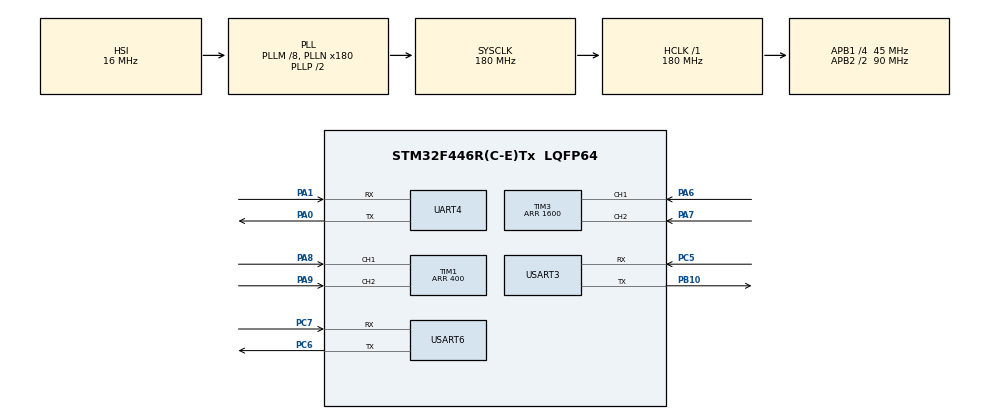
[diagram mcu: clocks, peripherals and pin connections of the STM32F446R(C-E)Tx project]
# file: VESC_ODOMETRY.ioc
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Dma.Request0=USART6_RX
Dma.Request1=UART4_RX
Dma.UART4_RX.1.Direction=DMA_PERIPH_TO_MEMORY
Dma.UART4_RX.1.FIFOMode=DMA_FIFOMODE_DISABLE
Dma.UART4_RX.1.Instance=DMA1_Stream2
Dma.UART4_RX.1.MemDataAlignment=DMA_MDATAALIGN_BYTE
Dma.UART4_RX.1.MemInc=DMA_MINC_ENABLE
Dma.UART4_RX.1.Mode=DMA_CIRCULAR
Dma.UART4_RX.1.PeriphDataAlignment=DMA_PDATAALIGN_BYTE
Dma.UART4_RX.1.PeriphInc=DMA_PINC_DISABLE
Dma.UART4_RX.1.Priority=DMA_PRIORITY_LOW
Dma.USART6_RX.0.Direction=DMA_PERIPH_TO_MEMORY
Dma.USART6_RX.0.FIFOMode=DMA_FIFOMODE_DISABLE
Dma.USART6_RX.0.Instance=DMA2_Stream1
Dma.USART6_RX.0.MemDataAlignment=DMA_MDATAALIGN_BYTE
Dma.USART6_RX.0.MemInc=DMA_MINC_ENABLE
Dma.USART6_RX.0.Mode=DMA_CIRCULAR
Dma.USART6_RX.0.PeriphDataAlignment=DMA_PDATAALIGN_BYTE
Dma.USART6_RX.0.PeriphInc=DMA_PINC_DISABLE
Dma.USART6_RX.0.Priority=DMA_PRIORITY_LOW
FREERTOS.Tasks01=Motor_run,24,128,motor_run_function,Default,NULL,Dynamic,NULL,NULL
Mcu.Family=STM32F4
Mcu.Name=STM32F446R(C-E)Tx
Mcu.Package=LQFP64
NVIC.DMA1_Stream2_IRQn=true\:5\:0\:false\:false\:true\:true\:false\:true\:true
NVIC.DMA2_Stream1_IRQn=true\:5\:0\:false\:false\:true\:true\:false\:true\:true
NVIC.PriorityGroup=NVIC_PRIORITYGROUP_4
PA0-WKUP.Mode=Asynchronous
PA0-WKUP.Signal=UART4_TX
PA1.Mode=Asynchronous
PA1.Signal=UART4_RX
PA13.Mode=Serial_Wire
PA13.Signal=SYS_JTMS-SWDIO
PA14.Mode=Serial_Wire
PA14.Signal=SYS_JTCK-SWCLK
PA6.Signal=S_TIM3_CH1
PA7.Signal=S_TIM3_CH2
PA8.Signal=S_TIM1_CH1
PA9.Signal=S_TIM1_CH2
PB10.Mode=Asynchronous
PB10.Signal=USART3_TX
PC5.Mode=Asynchronous
PC5.Signal=USART3_RX
PC6.Mode=Asynchronous
PC6.Signal=USART6_TX
PC7.Mode=Asynchronous
PC7.Signal=USART6_RX
PH0-OSC_IN.Mode=HSE-External-Oscillator
PH0-OSC_IN.Signal=RCC_OSC_IN
PH1-OSC_OUT.Mode=HSE-External-Oscillator
PH1-OSC_OUT.Signal=RCC_OSC_OUT
ProjectManager.HeapSize=0x200
ProjectManager.StackSize=0x400
ProjectManager.TargetToolchain=STM32CubeIDE
RCC.AHBFreq_Value=180000000
RCC.APB1CLKDivider=RCC_HCLK_DIV4
RCC.APB1Freq_Value=45000000
RCC.APB1TimFreq_Value=90000000
RCC.APB2CLKDivider=RCC_HCLK_DIV2
RCC.APB2Freq_Value=90000000
RCC.APB2TimFreq_Value=180000000
RCC.CortexFreq_Value=180000000
RCC.HCLKFreq_Value=180000000
RCC.PLLM=8
RCC.PLLN=180
RCC.SYSCLKFreq_VALUE=180000000
RCC.SYSCLKSource=RCC_SYSCLKSOURCE_PLLCLK
RCC.USBFreq_Value=180000000
RCC.VCOOutputFreq_Value=360000000
SH.S_TIM1_CH1.0=TIM1_CH1,Encoder_Interface
SH.S_TIM1_CH2.0=TIM1_CH2,Encoder_Interface
SH.S_TIM3_CH1.0=TIM3_CH1,Encoder_Interface
SH.S_TIM3_CH2.0=TIM3_CH2,Encoder_Interface
TIM1.AutoReloadPreload=TIM_AUTORELOAD_PRELOAD_ENABLE
TIM1.EncoderMode=TIM_ENCODERMODE_TI12
TIM1.Period=400
TIM2.Period=90000
TIM3.AutoReloadPreload=TIM_AUTORELOAD_PRELOAD_ENABLE
TIM3.EncoderMode=TIM_ENCODERMODE_TI12
TIM3.Period=1600
UART4.VirtualMode=Asynchronous
USART3.VirtualMode=VM_ASYNC
USART6.VirtualMode=VM_ASYNC
VP_FREERTOS_VS_CMSIS_V2.Mode=CMSIS_V2
VP_TIM2_VS_ClockSourceINT.Mode=Internal
board=custom

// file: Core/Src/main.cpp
/* USER CODE BEGIN Header */
/**
  ******************************************************************************
  * @file           : main.c
  * @brief          : Main program body
  ******************************************************************************
  * @attention
  *
  * Copyright (c) 2025 STMicroelectronics.
  * All rights reserved.
  *
  * This software is licensed under terms that can be found in the LICENSE file
  * in the root directory of this software component.
  * If no LICENSE file comes with this software, it is provided AS-IS.
  *
  ******************************************************************************
  */
/* USER CODE END Header */
#include "main.h"
#include "cmsis_os.h"

/* USER CODE BEGIN Includes */
#include "VescUart.h"

/* USER CODE END Includes */

TIM_HandleTypeDef htim1;
TIM_HandleTypeDef htim2;
TIM_HandleTypeDef htim3;

UART_HandleTypeDef huart4;
UART_HandleTypeDef huart3;
UART_HandleTypeDef huart6;
DMA_HandleTypeDef hdma_uart4_rx;
DMA_HandleTypeDef hdma_usart6_rx;

/* Definitions for Motor_run */
osThreadId_t Motor_runHandle;
const osThreadAttr_t Motor_run_attributes = {
  .name = "Motor_run",
  .stack_size = 128 * 4,
  .priority = (osPriority_t) osPriorityNormal,
};

void SystemClock_Config(void);
static void MX_GPIO_Init(void);
static void MX_DMA_Init(void);
static void MX_TIM1_Init(void);
static void MX_TIM3_Init(void);
static void MX_UART4_Init(void);
static void MX_USART3_UART_Init(void);
static void MX_USART6_UART_Init(void);
static void MX_TIM2_Init(void);
void motor_run_function(void *argument);

/* USER CODE BEGIN 0 */
VescUart vesc;
  // Motor 1
/* USER CODE END 0 */

int main(void)
{

  /* MCU Configuration--------------------------------------------------------*/

  /* Reset of all peripherals, Initializes the Flash interface and the Systick. */
  HAL_Init();

  /* Configure the system clock */
  SystemClock_Config();

  /* Initialize all configured peripherals */
  MX_GPIO_Init();
  MX_DMA_Init();
  MX_TIM1_Init();
  MX_TIM3_Init();
  MX_UART4_Init();
  MX_USART3_UART_Init();
  MX_USART6_UART_Init();
  MX_TIM2_Init();
  /* USER CODE BEGIN 2 */

  vesc.setSerialPort(&huart3);  // Motor 1
  /* USER CODE END 2 */

  /* Init scheduler */
  osKernelInitialize();

  /* Create the thread(s) */
  /* creation of Motor_run */
  Motor_runHandle = osThreadNew(motor_run_function, NULL, &Motor_run_attributes);

  /* Start scheduler */
  osKernelStart();

  /* We should never get here as control is now taken by the scheduler */

  /* Infinite loop */
  while (1)
  {

  }
}

void SystemClock_Config(void)
{
  RCC_OscInitTypeDef RCC_OscInitStruct = {0};
  RCC_ClkInitTypeDef RCC_ClkInitStruct = {0};

  /** Configure the main internal regulator output voltage
  */
  __HAL_RCC_PWR_CLK_ENABLE();
  __HAL_PWR_VOLTAGESCALING_CONFIG(PWR_REGULATOR_VOLTAGE_SCALE1);

  /** Initializes the RCC Oscillators according to the specified parameters
  * in the RCC_OscInitTypeDef structure.
  */
  RCC_OscInitStruct.OscillatorType = RCC_OSCILLATORTYPE_HSI;
  RCC_OscInitStruct.HSIState = RCC_HSI_ON;
  RCC_OscInitStruct.HSICalibrationValue = RCC_HSICALIBRATION_DEFAULT;
  RCC_OscInitStruct.PLL.PLLState = RCC_PLL_ON;
  RCC_OscInitStruct.PLL.PLLSource = RCC_PLLSOURCE_HSI;
  RCC_OscInitStruct.PLL.PLLM = 8;
  RCC_OscInitStruct.PLL.PLLN = 180;
  RCC_OscInitStruct.PLL.PLLP = RCC_PLLP_DIV2;
  RCC_OscInitStruct.PLL.PLLQ = 2;
  RCC_OscInitStruct.PLL.PLLR = 2;
  if (HAL_RCC_OscConfig(&RCC_OscInitStruct) != HAL_OK)
  {
    Error_Handler();
  }

  /** Activate the Over-Drive mode
  */
  if (HAL_PWREx_EnableOverDrive() != HAL_OK)
  {
    Error_Handler();
  }

  /** Initializes the CPU, AHB and APB buses clocks
  */
  RCC_ClkInitStruct.ClockType = RCC_CLOCKTYPE_HCLK|RCC_CLOCKTYPE_SYSCLK
                              |RCC_CLOCKTYPE_PCLK1|RCC_CLOCKTYPE_PCLK2;
  RCC_ClkInitStruct.SYSCLKSource = RCC_SYSCLKSOURCE_PLLCLK;
  RCC_ClkInitStruct.AHBCLKDivider = RCC_SYSCLK_DIV1;
  RCC_ClkInitStruct.APB1CLKDivider = RCC_HCLK_DIV4;
  RCC_ClkInitStruct.APB2CLKDivider = RCC_HCLK_DIV2;

  if (HAL_RCC_ClockConfig(&RCC_ClkInitStruct, FLASH_LATENCY_5) != HAL_OK)
  {
    Error_Handler();
  }
}

static void MX_TIM1_Init(void)
{

  TIM_Encoder_InitTypeDef sConfig = {0};
  TIM_MasterConfigTypeDef sMasterConfig = {0};

  htim1.Instance = TIM1;
  htim1.Init.Prescaler = 0;
  htim1.Init.CounterMode = TIM_COUNTERMODE_UP;
  htim1.Init.Period = 400;
  htim1.Init.ClockDivision = TIM_CLOCKDIVISION_DIV1;
  htim1.Init.RepetitionCounter = 0;
  htim1.Init.AutoReloadPreload = TIM_AUTORELOAD_PRELOAD_ENABLE;
  sConfig.EncoderMode = TIM_ENCODERMODE_TI12;
  sConfig.IC1Polarity = TIM_ICPOLARITY_RISING;
  sConfig.IC1Selection = TIM_ICSELECTION_DIRECTTI;
  sConfig.IC1Prescaler = TIM_ICPSC_DIV1;
  sConfig.IC1Filter = 0;
  sConfig.IC2Polarity = TIM_ICPOLARITY_RISING;
  sConfig.IC2Selection = TIM_ICSELECTION_DIRECTTI;
  sConfig.IC2Prescaler = TIM_ICPSC_DIV1;
  sConfig.IC2Filter = 0;
  if (HAL_TIM_Encoder_Init(&htim1, &sConfig) != HAL_OK)
  {
    Error_Handler();
  }
  sMasterConfig.MasterOutputTrigger = TIM_TRGO_RESET;
  sMasterConfig.MasterSlaveMode = TIM_MASTERSLAVEMODE_DISABLE;
  if (HAL_TIMEx_MasterConfigSynchronization(&htim1, &sMasterConfig) != HAL_OK)
  {
    Error_Handler();
  }

}

static void MX_TIM2_Init(void)
{

  TIM_ClockConfigTypeDef sClockSourceConfig = {0};
  TIM_MasterConfigTypeDef sMasterConfig = {0};

  htim2.Instance = TIM2;
  htim2.Init.Prescaler = 0;
  htim2.Init.CounterMode = TIM_COUNTERMODE_UP;
  htim2.Init.Period = 90000;
  htim2.Init.ClockDivision = TIM_CLOCKDIVISION_DIV1;
  htim2.Init.AutoReloadPreload = TIM_AUTORELOAD_PRELOAD_DISABLE;
  if (HAL_TIM_Base_Init(&htim2) != HAL_OK)
  {
    Error_Handler();
  }
  sClockSourceConfig.ClockSource = TIM_CLOCKSOURCE_INTERNAL;
  if (HAL_TIM_ConfigClockSource(&htim2, &sClockSourceConfig) != HAL_OK)
  {
    Error_Handler();
  }
  sMasterConfig.MasterOutputTrigger = TIM_TRGO_RESET;
  sMasterConfig.MasterSlaveMode = TIM_MASTERSLAVEMODE_DISABLE;
  if (HAL_TIMEx_MasterConfigSynchronization(&htim2, &sMasterConfig) != HAL_OK)
  {
    Error_Handler();
  }

}

static void MX_TIM3_Init(void)
{

  TIM_Encoder_InitTypeDef sConfig = {0};
  TIM_MasterConfigTypeDef sMasterConfig = {0};

  htim3.Instance = TIM3;
  htim3.Init.Prescaler = 0;
  htim3.Init.CounterMode = TIM_COUNTERMODE_UP;
  htim3.Init.Period = 1600;
  htim3.Init.ClockDivision = TIM_CLOCKDIVISION_DIV1;
  htim3.Init.AutoReloadPreload = TIM_AUTORELOAD_PRELOAD_ENABLE;
  sConfig.EncoderMode = TIM_ENCODERMODE_TI12;
  sConfig.IC1Polarity = TIM_ICPOLARITY_RISING;
  sConfig.IC1Selection = TIM_ICSELECTION_DIRECTTI;
  sConfig.IC1Prescaler = TIM_ICPSC_DIV1;
  sConfig.IC1Filter = 0;
  sConfig.IC2Polarity = TIM_ICPOLARITY_RISING;
  sConfig.IC2Selection = TIM_ICSELECTION_DIRECTTI;
  sConfig.IC2Prescaler = TIM_ICPSC_DIV1;
  sConfig.IC2Filter = 0;
  if (HAL_TIM_Encoder_Init(&htim3, &sConfig) != HAL_OK)
  {
    Error_Handler();
  }
  sMasterConfig.MasterOutputTrigger = TIM_TRGO_RESET;
  sMasterConfig.MasterSlaveMode = TIM_MASTERSLAVEMODE_DISABLE;
  if (HAL_TIMEx_MasterConfigSynchronization(&htim3, &sMasterConfig) != HAL_OK)
  {
    Error_Handler();
  }

}

static void MX_UART4_Init(void)
{

  huart4.Instance = UART4;
  huart4.Init.BaudRate = 115200;
  huart4.Init.WordLength = UART_WORDLENGTH_8B;
  huart4.Init.StopBits = UART_STOPBITS_1;
  huart4.Init.Parity = UART_PARITY_NONE;
  huart4.Init.Mode = UART_MODE_TX_RX;
  huart4.Init.HwFlowCtl = UART_HWCONTROL_NONE;
  huart4.Init.OverSampling = UART_OVERSAMPLING_16;
  if (HAL_UART_Init(&huart4) != HAL_OK)
  {
    Error_Handler();
  }

}

static void MX_USART3_UART_Init(void)
{

  huart3.Instance = USART3;
  huart3.Init.BaudRate = 115200;
  huart3.Init.WordLength = UART_WORDLENGTH_8B;
  huart3.Init.StopBits = UART_STOPBITS_1;
  huart3.Init.Parity = UART_PARITY_NONE;
  huart3.Init.Mode = UART_MODE_TX_RX;
  huart3.Init.HwFlowCtl = UART_HWCONTROL_NONE;
  huart3.Init.OverSampling = UART_OVERSAMPLING_16;
  if (HAL_UART_Init(&huart3) != HAL_OK)
  {
    Error_Handler();
  }

}

static void MX_USART6_UART_Init(void)
{

  huart6.Instance = USART6;
  huart6.Init.BaudRate = 115200;
  huart6.Init.WordLength = UART_WORDLENGTH_8B;
  huart6.Init.StopBits = UART_STOPBITS_1;
  huart6.Init.Parity = UART_PARITY_NONE;
  huart6.Init.Mode = UART_MODE_TX_RX;
  huart6.Init.HwFlowCtl = UART_HWCONTROL_NONE;
  huart6.Init.OverSampling = UART_OVERSAMPLING_16;
  if (HAL_UART_Init(&huart6) != HAL_OK)
  {
    Error_Handler();
  }

}

static void MX_DMA_Init(void)
{

  /* DMA controller clock enable */
  __HAL_RCC_DMA2_CLK_ENABLE();
  __HAL_RCC_DMA1_CLK_ENABLE();

  /* DMA interrupt init */
  /* DMA1_Stream2_IRQn interrupt configuration */
  HAL_NVIC_SetPriority(DMA1_Stream2_IRQn, 5, 0);
  HAL_NVIC_EnableIRQ(DMA1_Stream2_IRQn);
  /* DMA2_Stream1_IRQn interrupt configuration */
  HAL_NVIC_SetPriority(DMA2_Stream1_IRQn, 5, 0);
  HAL_NVIC_EnableIRQ(DMA2_Stream1_IRQn);

}

static void MX_GPIO_Init(void)
{

  /* GPIO Ports Clock Enable */
  __HAL_RCC_GPIOH_CLK_ENABLE();
  __HAL_RCC_GPIOA_CLK_ENABLE();
  __HAL_RCC_GPIOC_CLK_ENABLE();
  __HAL_RCC_GPIOB_CLK_ENABLE();

}

void motor_run_function(void *argument)
{
  /* USER CODE BEGIN 5 */
  /* Infinite loop */
  for(;;)
  {

	   vesc.setRPM(0.5); // Set speed for motor 1

	        // Set motor 2 speed (e.g., backward with speed 0.5)
	   vesc.setRPM(-0.5); // Set speed for motor 2

	        // Set motor 3 speed (e.g., forward with speed 0.5)
	  vesc.setRPM(0.5); // Set speed for motor 3
      osDelay(1);
  }
  /* USER CODE END 5 */
}

void Error_Handler(void)
{
  __disable_irq();
  while (1)
  {
  }
}
